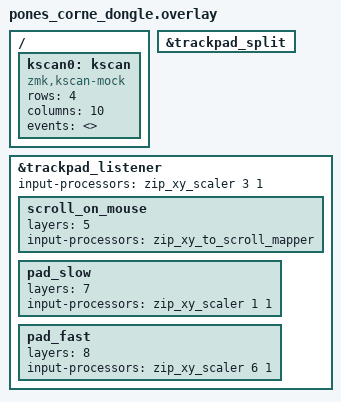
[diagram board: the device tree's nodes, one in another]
/* SPDX-License-Identifier: MIT */

#include "pones_corne.dtsi"
#include <input/processors.dtsi>

/ {
    /* The central receives every key over BLE; never synthesize local events. */
    kscan0: kscan {
        compatible = "zmk,kscan-mock";
        rows = <4>;
        columns = <10>;
        events = <>;
    };
};

&trackpad_split {
    status = "okay";
};

/* Only the dongle converts the right peripheral's input into host HID. */
&trackpad_listener {
    status = "okay";
    /* x3 cursor speed with fractional remainders, as in the previous working firmware. */
    input-processors = <&zip_xy_scaler 3 1>;

    /* Overrides replace the base chain and the first matching one wins, so
     * MOUSE scroll stays ahead of the speed toggles. No process-next. */
    scroll_on_mouse {
        layers = <5>; /* MOUSE in pones_corne.keymap. */
        /* Unscaled scroll as in the previous firmware. */
        input-processors = <&zip_xy_to_scroll_mapper>;
    };

    /* Factory "DPI Slow" / "DPI Fast" multipliers, toggled from SYS+D / SYS+E. */
    pad_slow {
        layers = <7>; /* PAD_SLOW */
        input-processors = <&zip_xy_scaler 1 1>;
    };

    pad_fast {
        layers = <8>; /* PAD_FAST */
        input-processors = <&zip_xy_scaler 6 1>;
    };
};
/* No zip_temp_layer: pad activity must remain cursor motion off MOUSE. */
